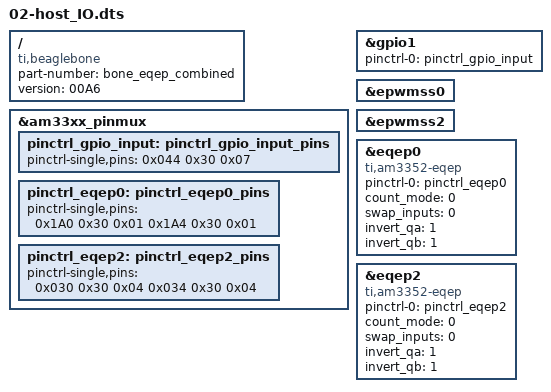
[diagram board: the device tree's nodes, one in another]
// SPDX-License-Identifier: GPL-2.0-only
/*
 * Combined eQEP0, eQEP2 (alternate pins) & P9.23 (Input Pull-up)
 * Targets BeagleBone Black - Kernel 6.12+ (Debian 12)
 * 3-cell format: <offset flags mode>
 */

/dts-v1/;
/plugin/;

/ {
    compatible = "ti,beaglebone", "ti,beaglebone-black";

    /* Identification */
    part-number = "bone_eqep_combined";
    version = "00A6";

    fragment@0 {
        target = <&am33xx_pinmux>;
        __overlay__ {

            /* Groupe GPIO : P9.23 (conf_gpmc_a1 = GPIO1[17]) */
            pinctrl_gpio_input: pinctrl_gpio_input_pins {
                pinctrl-single,pins = <
                    0x044 0x30 0x07  /* P9_23: Input + pull-up, Mode 7 */
                >;
            };

            /* Groupe eQEP0 : P9.42 & P9.27 */
            pinctrl_eqep0: pinctrl_eqep0_pins {
                pinctrl-single,pins = <
                    0x1A0 0x30 0x01  /* P9_42 = EQEP0A, MODE1 */
                    0x1A4 0x30 0x01  /* P9_27 = EQEP0B, MODE1 */
                >;
            };

            /* Groupe eQEP2 (Alternate) : P8.12 & P8.11 */
            pinctrl_eqep2: pinctrl_eqep2_pins {
                pinctrl-single,pins = <
                    0x030 0x30 0x04  /* P8_12 = EQEP2A_in, MODE4 */
                    0x034 0x30 0x04  /* P8_11 = EQEP2B_in, MODE4 */
                >;
            };

            
        };
    };

    /* Attache pinmux P9_23 directement sur gpio1 (bone-pinmux-helper absent sur kernel 6.12) */
    fragment@1 {
        target = <&gpio1>;
        __overlay__ {
            pinctrl-names = "default";
            pinctrl-0 = <&pinctrl_gpio_input>;
        };
    };

    /* Activation ePWMSS 0 & 2 */
    fragment@2 {
        target = <&epwmss0>;
        __overlay__ { status = "okay"; };
    };

    fragment@3 {
        target = <&epwmss2>;
        __overlay__ { status = "okay"; };
    };

    /* Activation Hardware eQEP 0 */
    fragment@4 {
        target = <&eqep0>;
        __overlay__ {
            compatible = "ti,am3352-eqep";
            pinctrl-names = "default";
            pinctrl-0 = <&pinctrl_eqep0>;
            count_mode = <0>;
            swap_inputs = <0>;
            invert_qa = <1>;
            invert_qb = <1>;
            status = "okay";
        };
    };

    /* Activation Hardware eQEP 2 */
    fragment@5 {
        target = <&eqep2>;
        __overlay__ {
            compatible = "ti,am3352-eqep";
            pinctrl-names = "default";
            pinctrl-0 = <&pinctrl_eqep2>;
            count_mode = <0>;
            swap_inputs = <0>;
            invert_qa = <1>;
            invert_qb = <1>;
            status = "okay";
        };
    };
};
